# AE302F40C1537LE_CM55_HE_View register map
Vendor: Alif Semiconductor; Series: E3; File version: 1.0
CPU: CM55 r1p0, selectable endian, MPU, FPU, double-precision FPU, DSP, VTOR, 8 interrupt priority bits, 1 SAU regions
Registers are 32-bit, read-write, reset 0x0 unless marked. A register's access mark holds for its fields unless they carry their own. Offsets are from the block's base; [hi:lo] are bit positions; lines under a group give offsets from that group; {n}, {i} and the like mark numbered series.

## STOP_MODE
Base 0x1A60F000
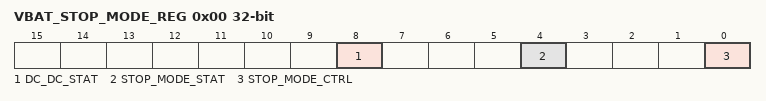
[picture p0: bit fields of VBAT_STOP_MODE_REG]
0x00 VBAT_STOP_MODE_REG — VBAT Stop Mode Control and Status Register
  [8] DC_DC_STAT ro — DC-DC Status Reflects the real-time status of DC-DC power
    0=DC-DC is ON; 1=DC-DC is OFF
  [4] STOP_MODE_STAT write-1-clears — Stop Mode Status - HW sets this bit when DC-DC was turned off - SW clears this bit by writing 0x1
  [0] STOP_MODE_CTRL — Stop Mode Control - SW sets this bit to enter stop mode - HW clears this bit when there is a wake-up event

## EVTRTR2
Base 0x400E2000
Same registers: EVTRTR0 0x49035000
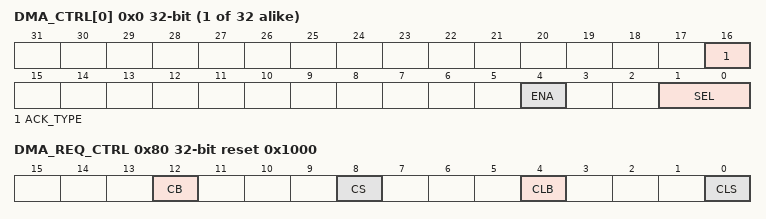
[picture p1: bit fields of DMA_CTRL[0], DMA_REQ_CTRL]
{0x0+4i} DMA_CTRL[{i}] (i=0..31) — DMA/Event Router Control and Status Register (n)
  [16] ACK_TYPE ro — DMA handshake type status for DMA peripheral
    0=Peripheral completes the REQ-ACK handshake with DMA controller. Event Router passing through REQ-ACK between DMA controller and peripheral.; 1=Event Router completes the REQ-ACK handshake with DMA controller. Peripheral raises DMA request without responding to ACK from DMA controller.
  [4] ENA — DMA channel enable
    0=Disable DMA channel; 1=Enable DMA channel
  [1:0] SEL — Select one channel from the four input groups Note: This field is only available for EVTRTR0. It is RESERVED and treated as RAZ/WI (read-as-zero, write-ignored) for EVTRTR1 and EVTRTR2.
    {v}=Select group {v} (v=0..3)
0x80 DMA_REQ_CTRL reset 0x1000 — DMA REQ Control Register
  [all] fields
    0=Disable; 1=Enable
  [12] CB — Enable DMA request on DMACBREQ
  [8] CS — Enable DMA request on DMACSREQ
  [4] CLB — Enable DMA request on DMACLBREQ
  [0] CLS — Enable DMA request on DMACLSREQ
0x90 DMA_ACK_TYPE0 reset 0xFFFFFF00 — DMA Handshake Type Register 0
  [31:0] ACK — Select DMA handshake type for DMA group #0
0x94 DMA_ACK_TYPE1 reset 0xFF3FF300 — DMA Handshake Type Register 1
  [31:0] ACK — Select DMA handshake type for DMA group #1
0x98 DMA_ACK_TYPE2 reset 0xC3FF0000 — DMA Handshake Type Register 2
  [31:0] ACK — Select DMA handshake type for DMA group #2
0x9C DMA_ACK_TYPE3 — DMA Handshake Type Register 3
  [31:0] ACK — Select DMA handshake type for DMA group #3

## WDT_HE_CTRL
Base 0x40100000
Same registers: WDT_HE_REFRESH 0x40101000
0x00 WDT_WDOGLOAD reset 0xFFFFFFFF — Watchdog Load Register
  [31:0] WDOGLOAD — When this bit field is written, the count is immediately restarted from the new value. The minimum valid value for this field is 0x1.
0x04 WDT_WDOGVALUE ro reset 0xFFFFFFFF — Watchdog Value Register
  [31:0] WDOGVALUE — This bit field gives the current value of the decrementing counter.
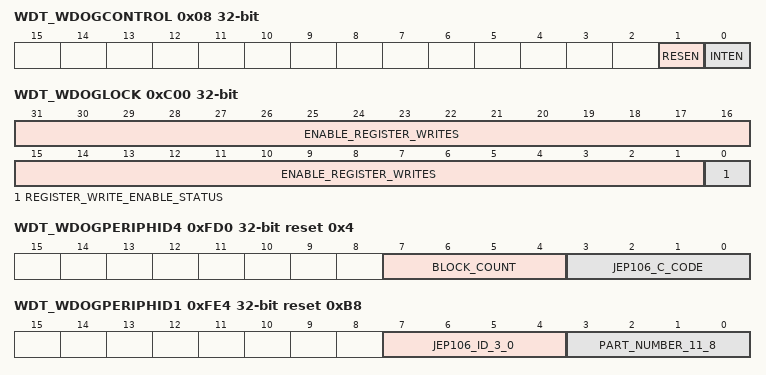
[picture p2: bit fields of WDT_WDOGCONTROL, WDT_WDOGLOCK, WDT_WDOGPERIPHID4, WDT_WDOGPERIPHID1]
0x08 WDT_WDOGCONTROL — Watchdog Control Register
  [1] RESEN — Enables the watchdog reset output, WDOGRES. Acts as a mask for the reset output.
    0=Reset is disabled; 1=Reset is enabled
  [0] INTEN — Enables the interrupt event, WDT_IRQ. Reloads the counter from the value in WDT_WDOGLOAD register when the interrupt is enabled, afterpreviously being disabled.
    0=The counter and the interrupt are disabled; 1=The counter and the interrupt are enabled
0x0C WDT_WDOGINTCLR wo reset not defined — Watchdog Clear Interrupt Register
  [31:0] WDOGINTCLR — A write of any value clears the watchdog interrupt, and reloads the counter from the value in WDT_WDOGLOAD register.
0x10 WDT_WDOGRIS ro — Watchdog Raw Interrupt Status Register
  [0] RAW_WATCHDOG_INTERRUPT — Enables the raw interrupt status from the counter. This value is ANDed with the value of WDT_WDOGCONTROL[INTEN] bit to create the masked interrupt.
0x14 WDT_WDOGMIS ro — Watchdog Interrupt Status Register
  [0] WATCHDOG_INTERRUPT — Enables the masked interrupt status from the counter. This value is the logical AND of the raw interrupt status with the WDT_WDOGCONTROL[INTEN] bit, and isthe value of the WDT_IRQ.
0xC00 WDT_WDOGLOCK — Watchdog Lock Register
  [31:1] ENABLE_REGISTER_WRITES — Enable write access to all other registers by writing 0x1ACC_E551. Disable write access by writing any other value.
  [0] REGISTER_WRITE_ENABLE_STATUS — Write access status:
    0=Write access to all other registers is enabled; 1=Write access to all other registers is disabled
0xFD0 WDT_WDOGPERIPHID4 ro reset 0x4 — Peripheral ID Register 4
  [7:4] BLOCK_COUNT
  [3:0] JEP106_C_CODE — JEP106 continuation code value
0xFE0 WDT_WDOGPERIPHID0 ro reset 0x24 — Peripheral ID Register 0
  [7:0] PART_NUMBER_7_0 — Part number
0xFE4 WDT_WDOGPERIPHID1 ro reset 0xB8 — Peripheral ID Register 1
  [7:4] JEP106_ID_3_0 — JEP106 identity code [3:0]
  [3:0] PART_NUMBER_11_8 — Part number
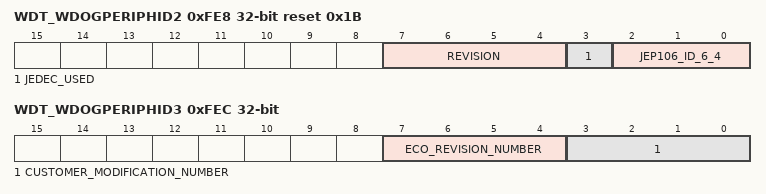
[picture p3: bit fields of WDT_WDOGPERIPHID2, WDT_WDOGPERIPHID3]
0xFE8 WDT_WDOGPERIPHID2 ro reset 0x1B — Peripheral ID Register 2
  [7:4] REVISION — Revision of the TZC-400
  [3] JEDEC_USED — Indicates that the TZC-400 uses a manufacturer identity code allocated by JEDEC according to JEP106.
  [2:0] JEP106_ID_6_4 — JEP106 identity code [6:4]
0xFEC WDT_WDOGPERIPHID3 ro — Peripheral ID Register 3
  [7:4] ECO_REVISION_NUMBER, [3:0] CUSTOMER_MODIFICATION_NUMBER
0xFF0 WDT_WDOGPCELLID0 ro reset 0xD — Component ID Register 0
  [7:0] COMPONENT_ID_0
0xFF4 WDT_WDOGPCELLID1 ro reset 0xF0 — Component ID Register 1
  [7:0] COMPONENT_ID_1
0xFF8 WDT_WDOGPCELLID2 ro reset 0x5 — Component ID Register 2
  [7:0] COMPONENT_ID_2
0xFFC WDT_WDOGPCELLID3 ro reset 0xB1 — Component ID Register 3
  [7:0] COMPONENT_ID_3
